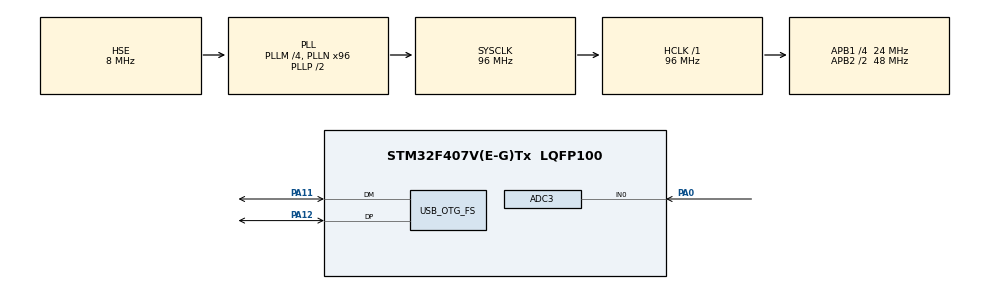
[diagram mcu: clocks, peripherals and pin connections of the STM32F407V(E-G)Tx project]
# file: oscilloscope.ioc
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Mcu.Family=STM32F4
Dma.ADC3.0.FIFOMode=DMA_FIFOMODE_DISABLE
USB_DEVICE.CLASS_NAME_FS=CDC
Dma.ADC3.0.Priority=DMA_PRIORITY_LOW
PH0-OSC_IN.Signal=RCC_OSC_IN
RCC.CortexFreq_Value=96000000
USB_DEVICE.VirtualModeFS=Cdc_FS
PA11.Mode=Device_Only
USB_DEVICE.VirtualMode-CDC_FS=Cdc
RCC.APB1CLKDivider=RCC_HCLK_DIV4
RCC.SYSCLKSource=RCC_SYSCLKSOURCE_PLLCLK
ProjectManager.StackSize=0x400
PA0-WKUP.Signal=ADCx_IN0
PA12.Signal=USB_OTG_FS_DP
ProjectManager.TargetToolchain=STM32CubeIDE
RCC.HCLKFreq_Value=96000000
VP_USB_DEVICE_VS_USB_DEVICE_CDC_FS.Mode=CDC_FS
RCC.APB2TimFreq_Value=96000000
Dma.ADC3.0.Direction=DMA_PERIPH_TO_MEMORY
TIM2.Channel-Output\ Compare2\ No\ Output=TIM_CHANNEL_2
NVIC.DMA2_Stream0_IRQn=true\:0\:0\:false\:false\:true\:false\:true
Dma.ADC3.0.MemDataAlignment=DMA_MDATAALIGN_HALFWORD
RCC.LSE_VALUE=32768
RCC.AHBFreq_Value=96000000
PH0-OSC_IN.Mode=HSE-External-Oscillator
ADC3.SamplingTime-1\#ChannelRegularConversion=ADC_SAMPLETIME_144CYCLES
RCC.HSE_VALUE=8000000
board=custom
RCC.VCOOutputFreq_Value=192000000
Dma.ADC3.0.PeriphInc=DMA_PINC_DISABLE
ADC3.ExternalTrigConv=ADC_EXTERNALTRIGCONV_T2_CC2
RCC.APB2Freq_Value=48000000
VP_TIM2_VS_ClockSourceINT.Mode=Internal
PH1-OSC_OUT.Signal=RCC_OSC_OUT
Dma.ADC3.0.MemInc=DMA_MINC_ENABLE
SH.ADCx_IN0.0=ADC3_IN0,IN0
TIM2.Period=4800-1
VP_TIM2_VS_no_output2.Mode=Output Compare2 No Output
Mcu.Name=STM32F407V(E-G)Tx
Dma.ADC3.0.PeriphDataAlignment=DMA_PDATAALIGN_HALFWORD
ADC3.Channel-1\#ChannelRegularConversion=ADC_CHANNEL_0
PH1-OSC_OUT.Mode=HSE-External-Oscillator
RCC.48MHZClocksFreq_Value=48000000
ADC3.Rank-1\#ChannelRegularConversion=1
RCC.SYSCLKFreq_VALUE=96000000
Mcu.Package=LQFP100
TIM2.OCMode_2=TIM_OCMODE_TOGGLE
PA12.Mode=Device_Only
NVIC.OTG_FS_IRQn=true\:0\:0\:false\:false\:true\:false\:true
PA11.Signal=USB_OTG_FS_DM
USB_OTG_FS.VirtualMode=Device_Only
ProjectManager.HeapSize=0x200
Dma.ADC3.0.Mode=DMA_CIRCULAR
RCC.HSI_VALUE=16000000
NVIC.PriorityGroup=NVIC_PRIORITYGROUP_4
ADC3.DMAContinuousRequests=ENABLE
RCC.APB2CLKDivider=RCC_HCLK_DIV2
RCC.PLLM=4
RCC.PLLN=96
ADC3.ExternalTrigConvEdge=ADC_EXTERNALTRIGCONVEDGE_RISINGFALLING
RCC.APB1TimFreq_Value=48000000
Dma.ADC3.0.Instance=DMA2_Stream0
RCC.APB1Freq_Value=24000000
Dma.Request0=ADC3
ADC3.NbrOfConversionFlag=1

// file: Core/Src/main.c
/* USER CODE BEGIN Header */
/**
  ******************************************************************************
  * @file           : main.c
  * @brief          : Main program body
  ******************************************************************************
  * @attention
  *
  * <h2><center>&copy; Copyright (c) 2021 STMicroelectronics.
  * All rights reserved.</center></h2>
  *
  * This software component is licensed by ST under BSD 3-Clause license,
  * the "License"; You may not use this file except in compliance with the
  * License. You may obtain a copy of the License at:
  *                        opensource.org/licenses/BSD-3-Clause
  *
  ******************************************************************************
  */
/* USER CODE END Header */
#include "main.h"
#include "usb_device.h"

/* USER CODE BEGIN PM */
#include "usbd_cdc_if.h"
/* USER CODE END PM */

ADC_HandleTypeDef hadc3;
DMA_HandleTypeDef hdma_adc3;

TIM_HandleTypeDef htim2;

/* USER CODE BEGIN PV */
short aData0[1000];
/* variable indicating that data from ADC are in memory */
uint8_t AdcConversionDone = 0;
/* USER CODE END PV *

/* USER CODE END PV */

void SystemClock_Config(void);
static void MX_GPIO_Init(void);
static void MX_DMA_Init(void);
static void MX_ADC3_Init(void);
static void MX_TIM2_Init(void);

int main(void)
{

  /* MCU Configuration--------------------------------------------------------*/

  /* Reset of all peripherals, Initializes the Flash interface and the Systick. */
  HAL_Init();

  /* Configure the system clock */
  SystemClock_Config();

  /* Initialize all configured peripherals */
  MX_GPIO_Init();
  MX_DMA_Init();
  MX_ADC3_Init();
  MX_TIM2_Init();
  MX_USB_DEVICE_Init();
  /* USER CODE BEGIN 2 */
  /*start ADC sampling into buffer*/
  HAL_ADC_Start_DMA(&hadc3, (uint32_t*)aData0, 1000);
  /*start TIM which triggers ADC conversions*/
  HAL_TIM_OC_Start(&htim2,TIM_CHANNEL_2);
  /* USER CODE END 2 */

  /* Infinite loop */
  while (1)
  {

    /* USER CODE BEGIN 3 */
	  if(AdcConversionDone>0){
	  /*CDC strucuture, where we check if the USB is transmithink*/

	 {
	  /*send data over usb, we have 1000 16bit samples which is 2000bytes*/
	  CDC_Transmit_FS((uint8_t*)aData0,2000);
	  /*indicate that after we receive new data we can send more*/
	  AdcConversionDone=0;
	  }
	  }
  }
  /* USER CODE END 3 */
}

void SystemClock_Config(void)
{
  RCC_OscInitTypeDef RCC_OscInitStruct = {0};
  RCC_ClkInitTypeDef RCC_ClkInitStruct = {0};

  /** Configure the main internal regulator output voltage
  */
  __HAL_RCC_PWR_CLK_ENABLE();
  __HAL_PWR_VOLTAGESCALING_CONFIG(PWR_REGULATOR_VOLTAGE_SCALE1);
  /** Initializes the RCC Oscillators according to the specified parameters
  * in the RCC_OscInitTypeDef structure.
  */
  RCC_OscInitStruct.OscillatorType = RCC_OSCILLATORTYPE_HSE;
  RCC_OscInitStruct.HSEState = RCC_HSE_ON;
  RCC_OscInitStruct.PLL.PLLState = RCC_PLL_ON;
  RCC_OscInitStruct.PLL.PLLSource = RCC_PLLSOURCE_HSE;
  RCC_OscInitStruct.PLL.PLLM = 4;
  RCC_OscInitStruct.PLL.PLLN = 96;
  RCC_OscInitStruct.PLL.PLLP = RCC_PLLP_DIV2;
  RCC_OscInitStruct.PLL.PLLQ = 4;
  if (HAL_RCC_OscConfig(&RCC_OscInitStruct) != HAL_OK)
  {
    Error_Handler();
  }
  /** Initializes the CPU, AHB and APB buses clocks
  */
  RCC_ClkInitStruct.ClockType = RCC_CLOCKTYPE_HCLK|RCC_CLOCKTYPE_SYSCLK
                              |RCC_CLOCKTYPE_PCLK1|RCC_CLOCKTYPE_PCLK2;
  RCC_ClkInitStruct.SYSCLKSource = RCC_SYSCLKSOURCE_PLLCLK;
  RCC_ClkInitStruct.AHBCLKDivider = RCC_SYSCLK_DIV1;
  RCC_ClkInitStruct.APB1CLKDivider = RCC_HCLK_DIV4;
  RCC_ClkInitStruct.APB2CLKDivider = RCC_HCLK_DIV2;

  if (HAL_RCC_ClockConfig(&RCC_ClkInitStruct, FLASH_LATENCY_3) != HAL_OK)
  {
    Error_Handler();
  }
}

static void MX_ADC3_Init(void)
{

  ADC_ChannelConfTypeDef sConfig = {0};

  /** Configure the global features of the ADC (Clock, Resolution, Data Alignment and number of conversion)
  */
  hadc3.Instance = ADC3;
  hadc3.Init.ClockPrescaler = ADC_CLOCK_SYNC_PCLK_DIV2;
  hadc3.Init.Resolution = ADC_RESOLUTION_12B;
  hadc3.Init.ScanConvMode = DISABLE;
  hadc3.Init.ContinuousConvMode = DISABLE;
  hadc3.Init.DiscontinuousConvMode = DISABLE;
  hadc3.Init.ExternalTrigConvEdge = ADC_EXTERNALTRIGCONVEDGE_RISINGFALLING;
  hadc3.Init.ExternalTrigConv = ADC_EXTERNALTRIGCONV_T2_CC2;
  hadc3.Init.DataAlign = ADC_DATAALIGN_RIGHT;
  hadc3.Init.NbrOfConversion = 1;
  hadc3.Init.DMAContinuousRequests = ENABLE;
  hadc3.Init.EOCSelection = ADC_EOC_SINGLE_CONV;
  if (HAL_ADC_Init(&hadc3) != HAL_OK)
  {
    Error_Handler();
  }
  /** Configure for the selected ADC regular channel its corresponding rank in the sequencer and its sample time.
  */
  sConfig.Channel = ADC_CHANNEL_0;
  sConfig.Rank = 1;
  sConfig.SamplingTime = ADC_SAMPLETIME_144CYCLES;
  if (HAL_ADC_ConfigChannel(&hadc3, &sConfig) != HAL_OK)
  {
    Error_Handler();
  }

}

static void MX_TIM2_Init(void)
{

  TIM_ClockConfigTypeDef sClockSourceConfig = {0};
  TIM_MasterConfigTypeDef sMasterConfig = {0};
  TIM_OC_InitTypeDef sConfigOC = {0};

  htim2.Instance = TIM2;
  htim2.Init.Prescaler = 0;
  htim2.Init.CounterMode = TIM_COUNTERMODE_UP;
  htim2.Init.Period = 4800-1;
  htim2.Init.ClockDivision = TIM_CLOCKDIVISION_DIV1;
  htim2.Init.AutoReloadPreload = TIM_AUTORELOAD_PRELOAD_DISABLE;
  if (HAL_TIM_Base_Init(&htim2) != HAL_OK)
  {
    Error_Handler();
  }
  sClockSourceConfig.ClockSource = TIM_CLOCKSOURCE_INTERNAL;
  if (HAL_TIM_ConfigClockSource(&htim2, &sClockSourceConfig) != HAL_OK)
  {
    Error_Handler();
  }
  if (HAL_TIM_OC_Init(&htim2) != HAL_OK)
  {
    Error_Handler();
  }
  sMasterConfig.MasterOutputTrigger = TIM_TRGO_RESET;
  sMasterConfig.MasterSlaveMode = TIM_MASTERSLAVEMODE_DISABLE;
  if (HAL_TIMEx_MasterConfigSynchronization(&htim2, &sMasterConfig) != HAL_OK)
  {
    Error_Handler();
  }
  sConfigOC.OCMode = TIM_OCMODE_TOGGLE;
  sConfigOC.Pulse = 0;
  sConfigOC.OCPolarity = TIM_OCPOLARITY_HIGH;
  sConfigOC.OCFastMode = TIM_OCFAST_DISABLE;
  if (HAL_TIM_OC_ConfigChannel(&htim2, &sConfigOC, TIM_CHANNEL_2) != HAL_OK)
  {
    Error_Handler();
  }

}

static void MX_DMA_Init(void)
{

  /* DMA controller clock enable */
  __HAL_RCC_DMA2_CLK_ENABLE();

  /* DMA interrupt init */
  /* DMA2_Stream0_IRQn interrupt configuration */
  HAL_NVIC_SetPriority(DMA2_Stream0_IRQn, 0, 0);
  HAL_NVIC_EnableIRQ(DMA2_Stream0_IRQn);

}

static void MX_GPIO_Init(void)
{

  /* GPIO Ports Clock Enable */
  __HAL_RCC_GPIOH_CLK_ENABLE();
  __HAL_RCC_GPIOA_CLK_ENABLE();

}

/* USER CODE BEGIN 4 */
void HAL_ADC_ConvCpltCallback(ADC_HandleTypeDef* hadc)
{
	AdcConversionDone=1;
}
/* USER CODE END 4 */

void Error_Handler(void)
{
  __disable_irq();
  while (1)
  {
  }
}

/************************ (C) COPYRIGHT STMicroelectronics *****END OF FILE****/
